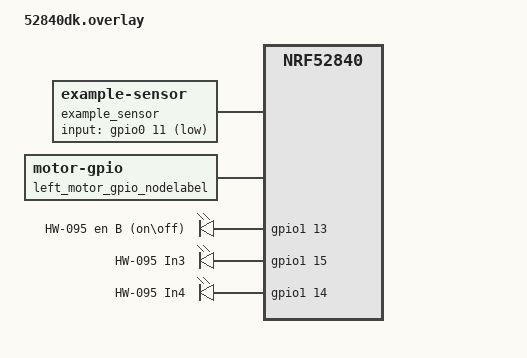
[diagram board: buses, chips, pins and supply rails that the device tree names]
/*
 * Copyright (c) 2021 Nordic Semiconductor ASA
 * SPDX-License-Identifier: Apache-2.0
 */

//  /dts-v1/;
#include <nordic/nrf52840_qiaa.dtsi>
// #include <zephyr/dt-bindings/pwm/pwm.h>
//  #include "custom_plank-pinctrl.dtsi"

/ {
    //  model = "Custom Plank Board";
    compatible = "vendor";

    //  chosen {
        //     //  zephyr,console = &uart0;
        //     //  zephyr,sram = &sram0;
        //     //  zephyr,flash = &flash0;
    //  };
    // aliases{
        //     motor-pwm-pin=&pwm_led0;
    // };
    example_sensor: example-sensor {
        compatible = "zephyr,example-sensor";
        input-gpios = <&gpio0 11 (GPIO_PULL_UP | GPIO_ACTIVE_LOW)>;
    };

    left_motor_gpio_nodelabel: left-motor-gpio-nodename{
        compatible = "motor-gpio";
        gals_property = "Learning";

    };
    //  motor_pwm_pin: motor-pwm-pin {
        //     // compatible = "pwms";
        //     pwms = <&pwm0 0 PWM_MSEC(20) PWM_POLARITY_INVERTED>;
        //     label = "Motor B EN pin";
    // };

    // blink_led: blink-led {
    //     compatible = "blink-gpio-led";
    //     led-gpios = <&gpio1 13 GPIO_ACTIVE_LOW>;
    //     blink-period-ms = <1000>;
    // };

    // pwmleds {
    //     compatible = "pwm-leds";
    //     motor_pwm_pin: pwm_led_0 {
    //         // pwms = <&pwm0 0 PWM_MSEC(500) PWM_POLARITY_NORMAL>;
    //         pwms = <&pwm0 0 PWM_MSEC(20) PWM_POLARITY_NORMAL>;
    //         label = "HW-095 EN B pin";
    //     };
    // };
    leds {
        compatible = "gpio-leds";
        motor_en_b: led_2 {
            gpios = <&gpio1 13 GPIO_ACTIVE_HIGH>;
            label = "HW-095 en B (on\off)";
        };
        motor_b_in_3: led_0 {
            gpios = <&gpio1 15 GPIO_ACTIVE_HIGH>;
            label = "HW-095 In3";
        };
        motor_b_in_4: led_1 {
            gpios = <&gpio1 14 GPIO_ACTIVE_HIGH>;
            label = "HW-095 In4";
        };

    };
};

//  &uicr {
    //      gpio-as-nreset;
//  };
// &pwm0 {
    //     status = "okay";
    //     pinctrl-0 = <&pwm0_default>;
    //     pinctrl-1 = <&pwm0_sleep>;
    //     pinctrl-names = "default", "sleep";
// };
// &pwm0 {
//     status = "okay";
//     pinctrl-0 = <&pwm0_default_custom>;
//     /delete-property/ pinctrl-1;
//     pinctrl-names = "default";
// };

// &pinctrl {
//     pwm0_default_custom: pwm0_default_custom {
//         group1 {
//             psels = <NRF_PSEL(PWM_OUT0, 1, 13)>; // P1.13
//             nordic,invert;
//         };
//     };
// };

&gpiote {
    status = "okay";
};

&gpio0 {
    status = "okay";
};
&gpio1 {
    status = "okay";
};
//  &uart0 {
    //      compatible = "nordic,nrf-uarte";
    //      status = "okay";

    //      current-speed = <115200>;
    //      pinctrl-0 = <&uart0_default>;
    //      pinctrl-1 = <&uart0_sleep>;
    //      pinctrl-names = "default", "sleep";
//  };
